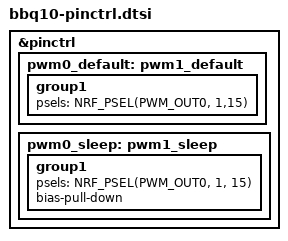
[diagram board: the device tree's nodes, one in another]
/*
 * Copyright (c) 2025  XixiLee-boom
 * SPDX-License-Identifier: MIT
 */

&pinctrl {

    pwm0_default:pwm1_default{
        group1{
            psels = <NRF_PSEL(PWM_OUT0, 1,15)>; // Backlight for Keyboard
        };
    };

    pwm0_sleep: pwm1_sleep {
        group1 {
            psels = <NRF_PSEL(PWM_OUT0, 1, 15)>;
            bias-pull-down;
        };
    };
}
